AUTOSAR XML (schema 00046)
standard types defined: float32, float64, sint16, sint32, sint8, uint16, uint32, uint8, void, boolean
package /ImplDataTypes
  impl type MultiStateBtnType: implementation-data-type=uint8, type-emitter=RTE
package /MappingSets
  data type mapping set MappingSet
package /PortInterfaces/SenderReceiver
  sender receiver interface SrIf_SeatCtrlBtns
    data DE_HeightBtnState: type=MultiStateBtnType
    data DE_InclinceBtnState: type=MultiStateBtnType
    data DE_SlideBtnState: type=MultiStateBtnType
  sender receiver interface SrIf_SeatCtrlData
    data DE_Height: type=uint8
    data DE_Incline: type=uint8
    data DE_Slide: type=uint8
package /SoftwareComponents
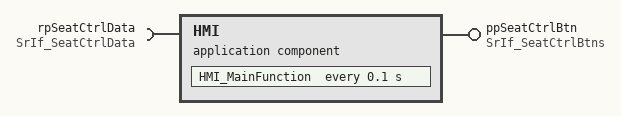
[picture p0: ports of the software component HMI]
  application sw component type HMI
    provide port ppSeatCtrlBtn: provided-interface=SrIf_SeatCtrlBtns
    require port rpSeatCtrlData: required-interface=SrIf_SeatCtrlData
    behavior Ibhv_HMI: data-type-mapping=MappingSet, handle-termination-and-restart=NO-SUPPORT
      timing event TE_HMI_MainFunction_100ms: start-on-event=HMI_MainFunction, period=0.1
      runnable HMI_MainFunction
        data-receive-point-by-arguments:
          access DRP_rpSeatCtrlData_DE_Height: accessed-variable=rpSeatCtrlData.DE_Height
          access DRP_rpSeatCtrlData_DE_Incline: accessed-variable=rpSeatCtrlData.DE_Incline
          access DRP_rpSeatCtrlData_DE_Slide: accessed-variable=rpSeatCtrlData.DE_Slide
        data-send-points:
          access DSP_ppSeatCtrlBtn_DE_HeightBtnState: accessed-variable=ppSeatCtrlBtn.DE_HeightBtnState
          access DSP_ppSeatCtrlBtn_DE_InclinceBtnState: accessed-variable=ppSeatCtrlBtn.DE_InclinceBtnState
          access DSP_ppSeatCtrlBtn_DE_SlideBtnState: accessed-variable=ppSeatCtrlBtn.DE_SlideBtnState
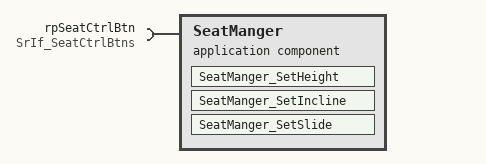
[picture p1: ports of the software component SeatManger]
  application sw component type SeatManger
    require port rpSeatCtrlBtn: required-interface=SrIf_SeatCtrlBtns
    behavior Ibhv_SeatManger: data-type-mapping=MappingSet, handle-termination-and-restart=NO-SUPPORT
      data received event DRE_rpSeatCtrlBtn_DE_HeightBtnState: start-on-event=SeatManger_SetHeight, data=rpSeatCtrlBtn.DE_HeightBtnState
      data received event DRE_rpSeatCtrlBtn_DE_InclinceBtnState: start-on-event=SeatManger_SetIncline, data=rpSeatCtrlBtn.DE_InclinceBtnState
      data received event DRE_rpSeatCtrlBtn_DE_SlideBtnState: start-on-event=SeatManger_SetSlide, data=rpSeatCtrlBtn.DE_SlideBtnState
      runnable SeatManger_SetHeight
        data-receive-point-by-arguments:
          access DRP_rpSeatCtrlBtn_DE_HeightBtnState: accessed-variable=rpSeatCtrlBtn.DE_HeightBtnState
      runnable SeatManger_SetIncline
        data-receive-point-by-arguments:
          access DRP_rpSeatCtrlBtn_DE_InclinceBtnState: accessed-variable=rpSeatCtrlBtn.DE_InclinceBtnState
      runnable SeatManger_SetSlide
        data-receive-point-by-arguments:
          access DRP_rpSeatCtrlBtn_DE_SlideBtnState: accessed-variable=rpSeatCtrlBtn.DE_SlideBtnState
  swc implementation Impl_HMI: programming-language=C, sw-version=1.0.0, vendor-id=255, behavior=Ibhv_HMI
    code-descriptors:
      code Code: artifact-descriptors=autosar-engineering-object={short-label=SWC.c, category=SWSRC}
    resource consumption ResourceConsumption
  swc implementation Impl_SeatManger: programming-language=C, sw-version=1.0.0, vendor-id=255, behavior=Ibhv_SeatManger
    code-descriptors:
      code Code: artifact-descriptors=autosar-engineering-object={short-label=SWC.c, category=SWSRC}
    resource consumption ResourceConsumption
package /Compositions
  composition sw component type TestAppComposition
    component HMI: type=HMI
    component SeatManger: type=SeatManger
    connect HMI.ppSeatCtrlBtn -> SeatManger.rpSeatCtrlBtn
